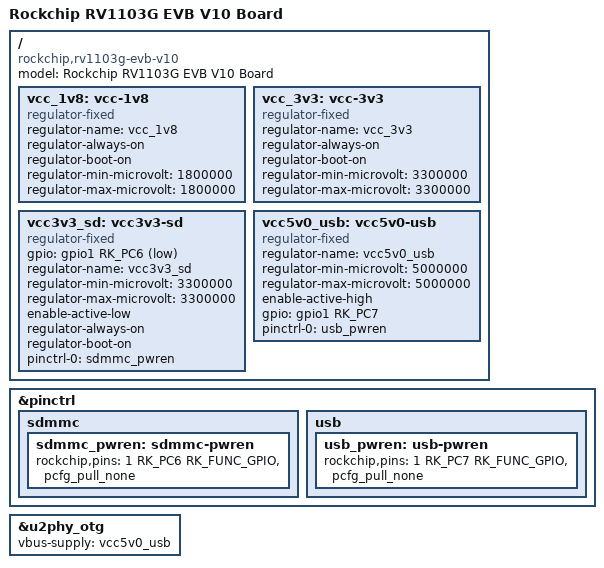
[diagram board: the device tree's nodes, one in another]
// SPDX-License-Identifier: (GPL-2.0+ OR MIT)
/*
 * Copyright (c) 2022 Rockchip Electronics Co., Ltd.
 */

/dts-v1/;

#include "rv1103.dtsi"
#include "rv1103-evb-v10.dtsi"
#include "rv1103-evb-cam.dtsi"

/ {
	model = "Rockchip RV1103G EVB V10 Board";
	compatible = "rockchip,rv1103g-evb-v10", "rockchip,rv1103";

	vcc_1v8: vcc-1v8 {
		compatible = "regulator-fixed";
		regulator-name = "vcc_1v8";
		regulator-always-on;
		regulator-boot-on;
		regulator-min-microvolt = <1800000>;
		regulator-max-microvolt = <1800000>;
	};

	vcc_3v3: vcc-3v3 {
		compatible = "regulator-fixed";
		regulator-name = "vcc_3v3";
		regulator-always-on;
		regulator-boot-on;
		regulator-min-microvolt = <3300000>;
		regulator-max-microvolt = <3300000>;
	};

	vcc3v3_sd: vcc3v3-sd {
		compatible = "regulator-fixed";
		gpio = <&gpio1 RK_PC6 GPIO_ACTIVE_LOW>;
		regulator-name = "vcc3v3_sd";
		regulator-min-microvolt = <3300000>;
		regulator-max-microvolt = <3300000>;
		enable-active-low;
		regulator-always-on;
		regulator-boot-on;
		pinctrl-names = "default";
		pinctrl-0 = <&sdmmc_pwren>;
	};

	vcc5v0_usb: vcc5v0-usb {
		compatible = "regulator-fixed";
		regulator-name = "vcc5v0_usb";
		regulator-min-microvolt = <5000000>;
		regulator-max-microvolt = <5000000>;
		enable-active-high;
		gpio = <&gpio1 RK_PC7 GPIO_ACTIVE_HIGH>;
		pinctrl-names = "default";
		pinctrl-0 = <&usb_pwren>;
	};
};

&pinctrl {
	sdmmc {
		/omit-if-no-ref/
		sdmmc_pwren: sdmmc-pwren {
			rockchip,pins = <1 RK_PC6 RK_FUNC_GPIO &pcfg_pull_none>;
		};
	};

	usb {
		usb_pwren: usb-pwren {
			rockchip,pins = <1 RK_PC7 RK_FUNC_GPIO &pcfg_pull_none>;
		};
	};
};

&u2phy_otg {
	vbus-supply = <&vcc5v0_usb>;
};
